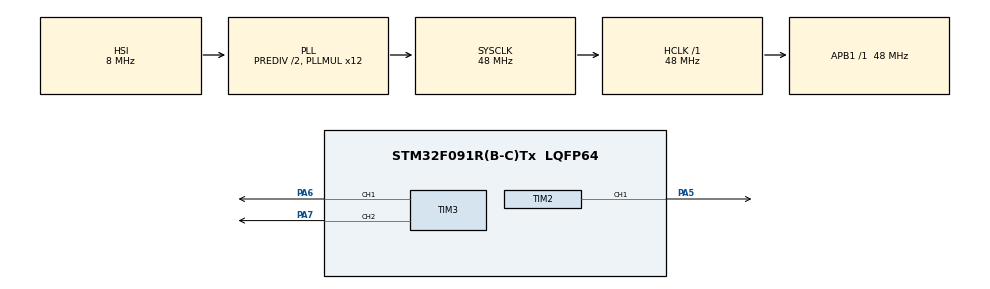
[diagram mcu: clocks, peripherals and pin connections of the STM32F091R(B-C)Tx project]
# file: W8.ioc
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Mcu.Family=STM32F0
Mcu.Name=STM32F091R(B-C)Tx
Mcu.Package=LQFP64
PA13.GPIO_Label=TMS
PA13.Mode=Serial_Wire
PA13.Signal=SYS_SWDIO
PA14.GPIO_Label=TCK
PA14.Mode=Serial_Wire
PA14.Signal=SYS_SWCLK
PA5.Signal=S_TIM2_CH1_ETR
PA6.Signal=S_TIM3_CH1
PA7.Signal=S_TIM3_CH2
PC14OSC32_IN.Mode=LSE-External-Oscillator
PC14OSC32_IN.Signal=RCC_OSC32_IN
PC15OSC32_OUT.Mode=LSE-External-Oscillator
PC15OSC32_OUT.Signal=RCC_OSC32_OUT
PF0-OSC_IN.Mode=HSE-External-Clock-Source
PF0-OSC_IN.Signal=RCC_OSC_IN
PF1-OSC_OUT.Signal=RCC_OSC_OUT
ProjectManager.HeapSize=0x200
ProjectManager.StackSize=0x400
ProjectManager.TargetToolchain=STM32CubeIDE
RCC.AHBFreq_Value=48000000
RCC.APB1Freq_Value=48000000
RCC.APB1TimFreq_Value=48000000
RCC.FLatency-AdvancedSettings=FLASH_LATENCY_1
RCC.HCLKFreq_Value=48000000
RCC.PLLDivider=RCC_PREDIV_DIV2
RCC.PLLMUL=RCC_PLL_MUL12
RCC.PREFETCH_ENABLE-AdvancedSettings=1
RCC.SYSCLKFreq_VALUE=48000000
RCC.SYSCLKSource=RCC_SYSCLKSOURCE_PLLCLK
SH.S_TIM2_CH1_ETR.0=TIM2_CH1,PWM Generation1 CH1
SH.S_TIM3_CH1.0=TIM3_CH1,PWM Generation1 CH1
SH.S_TIM3_CH2.0=TIM3_CH2,PWM Generation2 CH2
TIM2.Channel-PWM\ Generation1\ CH1=TIM_CHANNEL_1
TIM3.Channel-PWM\ Generation1\ CH1=TIM_CHANNEL_1
TIM3.Channel-PWM\ Generation2\ CH2=TIM_CHANNEL_2
board=NUCLEO-F091RC

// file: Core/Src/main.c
/* USER CODE BEGIN Header */
/**
  ******************************************************************************
  * @file           : main.c
  * @brief          : Main program body
  ******************************************************************************
  * @attention
  *
  * Copyright (c) 2024 STMicroelectronics.
  * All rights reserved.
  *
  * This software is licensed under terms that can be found in the LICENSE file
  * in the root directory of this software component.
  * If no LICENSE file comes with this software, it is provided AS-IS.
  *
  ******************************************************************************
  */
/* USER CODE END Header */
#include "main.h"

/* USER CODE BEGIN Includes */
#include "dimming.h"

/* USER CODE END Includes */

TIM_HandleTypeDef htim2;
TIM_HandleTypeDef htim3;

void SystemClock_Config(void);
static void MX_GPIO_Init(void);
static void MX_TIM2_Init(void);
static void MX_TIM3_Init(void);

int main(void)
{

  /* MCU Configuration--------------------------------------------------------*/

  /* Reset of all peripherals, Initializes the Flash interface and the Systick. */
  HAL_Init();

  /* Configure the system clock */
  SystemClock_Config();

  /* Initialize all configured peripherals */
  MX_GPIO_Init();
  MX_TIM2_Init();
  MX_TIM3_Init();
  /* USER CODE BEGIN 2 */
  int period = 1000;
  int prescaler = 479;
  TIM2 -> PSC = prescaler;
  TIM2 -> ARR = period;

  TIM3 -> PSC = prescaler;
  TIM3 -> ARR = period;

  HAL_TIM_PWM_Start(&htim2, TIM_CHANNEL_1);
  HAL_TIM_PWM_Start(&htim3, TIM_CHANNEL_1);
  HAL_TIM_PWM_Start(&htim3, TIM_CHANNEL_2);

  //GPIOA -> BSRR = 0b10000;
  //setGPIOA = &(GPIOA -> BSRR);
  //*setGPIOA = 0b100000;

    struct LEDstruct rLED = {0,period,0, &(TIM3 -> CCR1), 0, 1};
    struct LEDstruct gLED = {0,period,0, &(TIM2 -> CCR1), 1, 1};
    struct LEDstruct bLED = {0,period,0, &(TIM3 -> CCR2), 2, 1};

    Led_setPhaseShift(&rLED);
    Led_setPhaseShift(&gLED);
    Led_setPhaseShift(&bLED);
  /* USER CODE END 2 */

  /* Infinite loop */
  /* USER CODE BEGIN WHILE */
  while (1)
  {

	  Led_RgbTriangleIncr(&rLED);
	  Led_RgbTriangleIncr(&gLED);
	  Led_RgbTriangleIncr(&bLED);
	  HAL_Delay(5);

    /* USER CODE END WHILE */

  }
}

void SystemClock_Config(void)
{
  RCC_OscInitTypeDef RCC_OscInitStruct = {0};
  RCC_ClkInitTypeDef RCC_ClkInitStruct = {0};

  /** Initializes the RCC Oscillators according to the specified parameters
  * in the RCC_OscInitTypeDef structure.
  */
  RCC_OscInitStruct.OscillatorType = RCC_OSCILLATORTYPE_HSI;
  RCC_OscInitStruct.HSIState = RCC_HSI_ON;
  RCC_OscInitStruct.HSICalibrationValue = RCC_HSICALIBRATION_DEFAULT;
  RCC_OscInitStruct.PLL.PLLState = RCC_PLL_ON;
  RCC_OscInitStruct.PLL.PLLSource = RCC_PLLSOURCE_HSI;
  RCC_OscInitStruct.PLL.PLLMUL = RCC_PLL_MUL12;
  RCC_OscInitStruct.PLL.PREDIV = RCC_PREDIV_DIV2;
  if (HAL_RCC_OscConfig(&RCC_OscInitStruct) != HAL_OK)
  {
    Error_Handler();
  }

  /** Initializes the CPU, AHB and APB buses clocks
  */
  RCC_ClkInitStruct.ClockType = RCC_CLOCKTYPE_HCLK|RCC_CLOCKTYPE_SYSCLK
                              |RCC_CLOCKTYPE_PCLK1;
  RCC_ClkInitStruct.SYSCLKSource = RCC_SYSCLKSOURCE_PLLCLK;
  RCC_ClkInitStruct.AHBCLKDivider = RCC_SYSCLK_DIV1;
  RCC_ClkInitStruct.APB1CLKDivider = RCC_HCLK_DIV1;

  if (HAL_RCC_ClockConfig(&RCC_ClkInitStruct, FLASH_LATENCY_1) != HAL_OK)
  {
    Error_Handler();
  }
}

static void MX_TIM2_Init(void)
{

  TIM_MasterConfigTypeDef sMasterConfig = {0};
  TIM_OC_InitTypeDef sConfigOC = {0};

  htim2.Instance = TIM2;
  htim2.Init.Prescaler = 0;
  htim2.Init.CounterMode = TIM_COUNTERMODE_UP;
  htim2.Init.Period = 4294967295;
  htim2.Init.ClockDivision = TIM_CLOCKDIVISION_DIV1;
  htim2.Init.AutoReloadPreload = TIM_AUTORELOAD_PRELOAD_DISABLE;
  if (HAL_TIM_PWM_Init(&htim2) != HAL_OK)
  {
    Error_Handler();
  }
  sMasterConfig.MasterOutputTrigger = TIM_TRGO_RESET;
  sMasterConfig.MasterSlaveMode = TIM_MASTERSLAVEMODE_DISABLE;
  if (HAL_TIMEx_MasterConfigSynchronization(&htim2, &sMasterConfig) != HAL_OK)
  {
    Error_Handler();
  }
  sConfigOC.OCMode = TIM_OCMODE_PWM1;
  sConfigOC.Pulse = 0;
  sConfigOC.OCPolarity = TIM_OCPOLARITY_HIGH;
  sConfigOC.OCFastMode = TIM_OCFAST_DISABLE;
  if (HAL_TIM_PWM_ConfigChannel(&htim2, &sConfigOC, TIM_CHANNEL_1) != HAL_OK)
  {
    Error_Handler();
  }
  HAL_TIM_MspPostInit(&htim2);

}

static void MX_TIM3_Init(void)
{

  TIM_MasterConfigTypeDef sMasterConfig = {0};
  TIM_OC_InitTypeDef sConfigOC = {0};

  htim3.Instance = TIM3;
  htim3.Init.Prescaler = 0;
  htim3.Init.CounterMode = TIM_COUNTERMODE_UP;
  htim3.Init.Period = 65535;
  htim3.Init.ClockDivision = TIM_CLOCKDIVISION_DIV1;
  htim3.Init.AutoReloadPreload = TIM_AUTORELOAD_PRELOAD_DISABLE;
  if (HAL_TIM_PWM_Init(&htim3) != HAL_OK)
  {
    Error_Handler();
  }
  sMasterConfig.MasterOutputTrigger = TIM_TRGO_RESET;
  sMasterConfig.MasterSlaveMode = TIM_MASTERSLAVEMODE_DISABLE;
  if (HAL_TIMEx_MasterConfigSynchronization(&htim3, &sMasterConfig) != HAL_OK)
  {
    Error_Handler();
  }
  sConfigOC.OCMode = TIM_OCMODE_PWM1;
  sConfigOC.Pulse = 0;
  sConfigOC.OCPolarity = TIM_OCPOLARITY_HIGH;
  sConfigOC.OCFastMode = TIM_OCFAST_DISABLE;
  if (HAL_TIM_PWM_ConfigChannel(&htim3, &sConfigOC, TIM_CHANNEL_1) != HAL_OK)
  {
    Error_Handler();
  }
  if (HAL_TIM_PWM_ConfigChannel(&htim3, &sConfigOC, TIM_CHANNEL_2) != HAL_OK)
  {
    Error_Handler();
  }
  HAL_TIM_MspPostInit(&htim3);

}

static void MX_GPIO_Init(void)
{

  /* GPIO Ports Clock Enable */
  __HAL_RCC_GPIOC_CLK_ENABLE();
  __HAL_RCC_GPIOF_CLK_ENABLE();
  __HAL_RCC_GPIOA_CLK_ENABLE();

}

void Error_Handler(void)
{
  __disable_irq();
  while (1)
  {
  }
}
